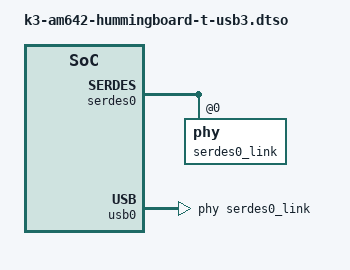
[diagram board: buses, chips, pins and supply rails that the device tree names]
// SPDX-License-Identifier: GPL-2.0+
/*
 * Copyright (C) 2023 Josua Mayer <josua@solid-run.com>
 *
 * Overlay for SolidRun AM642 HummingBoard-T to enable USB-3.1.
 */

/dts-v1/;
/plugin/;

#include <dt-bindings/phy/phy.h>

#include "k3-serdes.h"

&serdes0 {
	#address-cells = <1>;
	#size-cells = <0>;

	serdes0_link: phy@0 {
		reg = <0>;
		cdns,num-lanes = <1>;
		cdns,phy-type = <PHY_TYPE_USB3>;
		#phy-cells = <0>;
		resets = <&serdes_wiz0 1>;
	};
};

&serdes_ln_ctrl {
	idle-states = <AM64_SERDES0_LANE0_USB>;
};

&serdes_mux {
	idle-state = <0>;
};

&usbss0 {
	/delete-property/ ti,usb2-only;
};

&usb0 {
	maximum-speed = "super-speed";
	phys = <&serdes0_link>;
	phy-names = "cdns3,usb3-phy";
};
